# AE8SUPERSET_CM55_HP_View register map
Vendor: Alif Semiconductor; Series: E8; File version: 1.0
CPU: CM55 r1p0, selectable endian, MPU, FPU, double-precision FPU, DSP, VTOR, 8 interrupt priority bits, 1 SAU regions
Registers are 32-bit, read-write, reset 0x0 unless marked. A register's access mark holds for its fields unless they carry their own. Offsets are from the block's base; [hi:lo] are bit positions.

## REFCLK_CNT_BASE0
Base 0x1A230000
Same registers: REFCLK_CNT_BASE1 0x1A240000, REFCLK_CNT_BASE2 0x1A250000, REFCLK_CNT_BASE3 0x1A260000, S32KCLK_CNT_BASE0 0x1A430000, S32KCLK_CNT_BASE1 0x1A440000
0x00 CNTPCT_LO ro reset not defined — Physical Count Low Register
  [31:0] PHYS_CNT_VAL_LO — This field holds bits [31:0] of the 64-bit physical count value.
0x04 CNTPCT_HI ro reset not defined — Physical Count High Register
  [31:0] PHYS_CNT_VAL_HI — This field holds bits [63:32] of the 64-bit physical count value.
0x08 CNTVCT_LO ro reset not defined — Virtual Count Low Register
  [31:0] VIRT_CNT_VAL_LO — This field holds bits [31:0] of the 64-bit virtual count value.
0x0C CNTVCT_HI ro reset not defined — Virtual Count High Register
  [31:0] VIRT_CNT_VAL_HI — This field holds bits [63:32] of the 64-bit virtual count value.
0x10 RD_CNTFRQ ro reset not defined — Counter Frequency Register
  [31:0] CLK_FREQ — Read-only version of CNTFRQ. Indicates the counter clock frequency in Hz. This field is provided so that software can discover the counter frequency. The value of this field is not interpreted by hardware.
0x18 CNTVOFF_LO ro reset not defined — Virtual Offset Low Register
  [31:0] VIRT_OFFSET_LO — Bits [31:0] of the timer virtual offset value. This field is the read-only version of CNTVOFFn_LO. This is the offset between real time and virtual time.
0x1C CNTVOFF_HI ro reset not defined — Virtual Offset High Register
  [31:0] VIRT_OFFSET_HI — Bits [63:32] of the timer virtual offset value. This field is the read-only version of CNTVOFFn_HI. This is the offset between real time and virtual time.
0x20 CNTP_CVAL_LO reset not defined — Physical Timer Compare Value Low Register
  [31:0] CMP_VAL_LO — This field holds bits [31:0] of the 64-bit physical timer compare value. When CNTP_CTL[ENABLE] = 0x1, the timer condition is met when (CNTPCT_HI[31:0] to CNTPCT_LO[31:0]) - (CNTP_CVAL_HI[31:0] to CNTP_CVAL_LO[31:0]) is greater than or equal to zero. This means that CNTP_CVAL_HI and CNTP_CVAL_LO act like a 64-bit up counter timer. When the timer condition is met, the CNTP_CTL[ISTATUS] bit is set to 0x1, and if CNTP_CTL[IMASK] = 0x0, an interrupt is generated. When CNTP_CTL[ENABLE] = 0x0, the timer condition is not met, but CNTPCT_HI and CNTPCT_LO continue to count.
0x24 CNTP_CVAL_HI reset not defined — Physical Timer Compare Value High Register
  [31:0] CMP_VAL_HI — This field holds bits [63:32] of the 64-bit physical timer compare value. When CNTP_CTL[ENABLE] = 0x1, the timer condition is met when (CNTPCT_HI[31:0] to CNTPCT_LO[31:0]) - (CNTP_CVAL_HI[31:0] to CNTP_CVAL_LO[31:0]) is greater than or equal to zero. This means that CNTP_CVAL_HI and CNTP_CVAL_LO act like a 64-bit up counter timer. When the timer condition is met, the CNTP_CTL[ISTATUS] bit is set to 0x1, and if CNTP_CTL[IMASK] = 0x0, an interrupt is generated. When CNTP_CTL[ENABLE] = 0x0, the timer condition is not met, but CNTPCT_HI and CNTPCT_LO continue to count.
0x28 CNTP_TVAL reset not defined — Physical Timer Value Register
  [31:0] TMR_VAL — Holds the timer value for the physical timer. When reading from this register the value returned is (CNTP_CVAL_HI[31:0] to CNTP_CVAL_LO[31:0]) - (CNTPCT_HI[31:0] to CNTPCT_LO[31:0]), if CNTP_CTL[ENABLE] = 0x1. If CNTP_CTL[ENABLE] = 0x0, the value returned is unknown. When writing to this register the 64-bit compare value (CNTP_CVAL_HI[31:0] to CNTP_CVAL_LO[31:0]) is set to (CNTPCT_HI[31:0] to CNTPCT_LO[31:0]) + CNTP_TVAL, where CNTP_TVAL is treated as a signed 32-bit integer. When CNTP_CTL[ENABLE] = 0x1, the timer condition is met when (CNTPCT_HI[31:0] to CNTPCT_LO[31:0]) - (CNTP_CVAL_HI[31:0] to CNTP_CVAL_LO[31:0]) is greater than or equal to zero. This means that CNTP_TVAL acts like a 32-bit down counter timer. When the timer condition is met, the CNTP_CTL[ISTATUS] bit is set to 0x1, and if CNTP_CTL[IMASK] = 0x0, an interrupt is generated. When CNTP_CTL[ENABLE] = 0x0, the timer condition is not met, but CNTPCT_HI and CNTPCT_LO continue to count, so the CNTP_TVAL view appears to continue to count down.
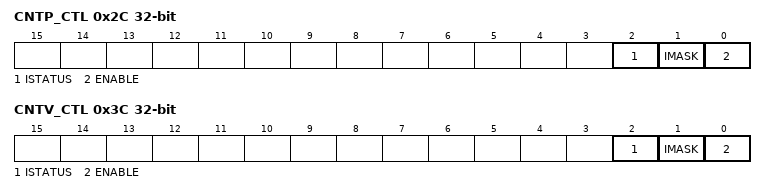
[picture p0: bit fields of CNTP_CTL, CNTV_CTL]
0x2C CNTP_CTL (reset mask 0xFFFFFFF8) — Physical Timer Control Register
  [2] ISTATUS ro — Timer status This bit indicates whether the timer condition is met when CNTP_CTL[ENABLE] = 0x1. It does not take into account the CNTP_CTL[IMASK] bit value. If ISTATUS = 0x1 and CNTP_CTL[IMASK] = 0x0, then the timer interrupt is asserted. When CNTP_CTL[ENABLE] = 0x0, the ISTATUS value is unknown.
    0=Timer condition is not met; 1=Timer condition is met
  [1] IMASK — Timer interrupt mask
    0=Timer interrupt is not masked; 1=Timer interrupt is masked
  [0] ENABLE — Timer enable Setting this bit to 0x0 disables the timer output signal, but the timer value accessible from CNTP_TVAL continues to count down.
    0=Timer disabled; 1=Timer enabled
0x30 CNTV_CVAL_LO reset not defined — Virtual Timer Compare Value Low Register
  [31:0] CMP_VAL_LO — This field holds bits [31:0] of the 64-bit virtual timer compare value. When CNTV_CTL[ENABLE] = 0x1, the timer condition is met when (CNTVCT_HI[31:0] to CNTVCT_LO[31:0]) - (CNTV_CVAL_HI[31:0] to CNTV_CVAL_LO[31:0]) is greater than or equal to zero. This means that CNTV_CVAL_HI and CNTV_CVAL_LO act like a 64-bit up counter timer. When the timer condition is met, the CNTV_CTL[ISTATUS] bit is set to 0x1, and if CNTV_CTL[IMASK] = 0x0, an interrupt is generated. When CNTV_CTL[ENABLE] = 0x0, the timer condition is not met, but CNTVCT_HI and CNTVCT_LO continue to count.
0x34 CNTV_CVAL_HI reset not defined — Virtual Timer Compare Value High Register
  [31:0] CMP_VAL_HI — This field holds bits [63:32] of the 64-bit virtual timer compare value. When CNTV_CTL[ENABLE] = 0x1, the timer condition is met when (CNTVCT_HI[31:0] to CNTVCT_LO[31:0]) - (CNTV_CVAL_HI[31:0] to CNTV_CVAL_LO[31:0]) is greater than or equal to zero. This means that CNTV_CVAL_HI and CNTV_CVAL_LO act like a 64-bit up counter timer. When the timer condition is met, the CNTV_CTL[ISTATUS] bit is set to 0x1, and if CNTV_CTL[IMASK] = 0x0, an interrupt is generated. When CNTV_CTL[ENABLE] = 0x0, the timer condition is not met, but CNTVCT_HI and CNTVCT_LO continue to count.
0x38 CNTV_TVAL reset not defined — Virtual Timer Value Register
  [31:0] TMR_VAL — Holds the timer value for the virtual timer. When reading from this register the value returned is (CNTV_CVAL_HI[31:0] to CNTV_CVAL_LO[31:0]) - (CNTVCT_HI[31:0] to CNTVCT_LO[31:0]), if CNTV_CTL[ENABLE] = 0x1. If CNTV_CTL[ENABLE] = 0x0, the value returned is unknown. When writing to this register the 64-bit compare value (CNTV_CVAL_HI[31:0] to CNTV_CVAL_LO[31:0]) is set to (CNTVCT_HI[31:0] to CNTVCT_LO[31:0]) + CNTV_TVAL, where CNTV_TVAL is treated as a signed 32-bit integer. When CNTV_CTL[ENABLE] = 0x1, the timer condition is met when (CNTVCT_HI[31:0] to CNTVCT_LO[31:0]) - (CNTV_CVAL_HI[31:0] to CNTV_CVAL_LO[31:0]) is greater than or equal to zero. This means that CNTV_TVAL acts like a 32-bit down counter timer. When the timer condition is met, the CNTV_CTL[ISTATUS] bit is set to 0x1, and if CNTV_CTL[IMASK] = 0x0, an interrupt is generated. When CNTV_CTL[ENABLE] = 0x0, the timer condition is not met, but CNTVCT_HI and CNTVCT_LO continue to count, so the CNTV_TVAL view appears to continue to count down.
0x3C CNTV_CTL (reset mask 0xFFFFFFF8) — Virtual Timer Control Register
  [2] ISTATUS ro — Timer status This bit indicates whether the timer condition is met when CNTV_CTL[ENABLE] = 0x1. It does not take into account the CNTV_CTL[IMASK] bit value. If ISTATUS = 0x1 and CNTV_CTL[IMASK] = 0x0, then the timer interrupt is asserted. When CNTV_CTL[ENABLE] = 0x0, the ISTATUS value is unknown.
    0=Timer condition is not met; 1=Timer condition is met
  [1] IMASK — Timer interrupt mask
    0=Timer interrupt is not masked; 1=Timer interrupt is masked
  [0] ENABLE — Timer enable Setting this bit to 0x0 disables the timer output signal, but the timer value accessible from CNTV_TVAL continues to count down.
    0=Timer disabled; 1=Timer enabled
